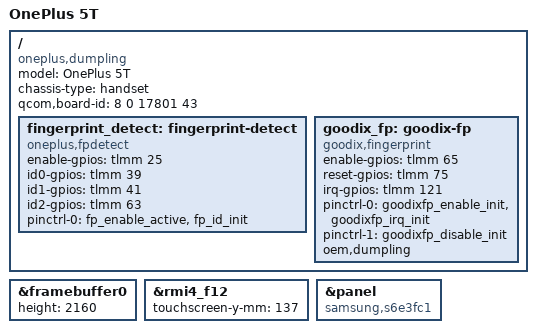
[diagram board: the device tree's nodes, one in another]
// SPDX-License-Identifier: BSD-3-Clause
/*
 * OnePlus 5T (dumpling) device tree
 *
 * Copyright (c) 2021, Jami Kettunen <jamipkettunen@gmail.com>
 */

#include "msm8998-oneplus-common.dtsi"

/ {
	model = "OnePlus 5T";
	compatible = "oneplus,dumpling", "qcom,msm8998";
	chassis-type = "handset";
	/* Required for bootloader to select correct board */
	qcom,board-id = <8 0 17801 43>;
};

/* Update the screen height values from 1920 to 2160 on the 5T */
&framebuffer0 {
	height = <2160>;
};

/* Adjust digitizer area height to match the 5T's taller panel */
&rmi4_f12 {
	touchscreen-y-mm = <137>;
};

&panel {
	compatible = "samsung,s6e3fc1";
};

/ {
	fingerprint_detect: fingerprint-detect {
		compatible = "oneplus,fpdetect";
		enable-gpios = <&tlmm 25 GPIO_ACTIVE_HIGH>;
		id0-gpios = <&tlmm 39 GPIO_ACTIVE_HIGH>;
		id1-gpios = <&tlmm 41 GPIO_ACTIVE_HIGH>;
		id2-gpios = <&tlmm 63 GPIO_ACTIVE_HIGH>;
		pinctrl-names = "default";
		pinctrl-0 = <&fp_enable_active &fp_id_init>;
	};

	goodix_fp: goodix-fp {
		compatible = "goodix,fingerprint";
		enable-gpios = <&tlmm 65 GPIO_ACTIVE_HIGH>;
		reset-gpios = <&tlmm 75 GPIO_ACTIVE_HIGH>;
		irq-gpios = <&tlmm 121 GPIO_ACTIVE_HIGH>;
		pinctrl-names = "fp_en_init", "fp_dis_init";
		pinctrl-0 = <&goodixfp_enable_init &goodixfp_irq_init>;
		pinctrl-1 = <&goodixfp_disable_init>;
		oem,dumpling;
	};
};
